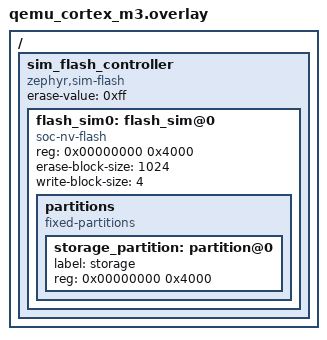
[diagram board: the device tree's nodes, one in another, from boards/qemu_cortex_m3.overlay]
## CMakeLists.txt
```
# SPDX-License-Identifier: Apache-2.0
cmake_minimum_required(VERSION 3.20.0)
find_package(Zephyr REQUIRED HINTS $ENV{ZEPHYR_BASE})
project(__name___tests)

set(LIB ${CMAKE_CURRENT_LIST_DIR}/../../lib)
target_include_directories(app PRIVATE ${LIB}/cfg)
target_sources(app PRIVATE ${LIB}/cfg/cfg.c src/test_cfg.c)
```

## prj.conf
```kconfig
CONFIG_ZTEST=y
CONFIG_FLASH=y
CONFIG_FLASH_MAP=y
CONFIG_NVS=y
CONFIG_SETTINGS=y
CONFIG_SETTINGS_NVS=y
```

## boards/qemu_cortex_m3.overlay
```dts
/* qemu has no writable flash: a 16 KiB simulated one with the storage_partition settings use */
/ {
	sim_flash_controller: sim_flash_controller {
		compatible = "zephyr,sim-flash";
		#address-cells = <1>;
		#size-cells = <1>;
		erase-value = <0xff>;

		flash_sim0: flash_sim@0 {
			compatible = "soc-nv-flash";
			reg = <0x00000000 0x4000>;
			erase-block-size = <1024>;
			write-block-size = <4>;

			partitions {
				compatible = "fixed-partitions";
				#address-cells = <1>;
				#size-cells = <1>;

				storage_partition: partition@0 {
					label = "storage";
					reg = <0x00000000 0x4000>;
				};
			};
		};
	};
};
```

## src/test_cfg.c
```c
#include <string.h>
#include <zephyr/ztest.h>
#include <zephyr/storage/flash_map.h>
#include "cfg.h"

static void *setup(void)
{
	const struct flash_area *fa;

	zassert_ok(flash_area_open(PARTITION_ID(storage_partition), &fa));
	zassert_ok(flash_area_erase(fa, 0, fa->fa_size));
	flash_area_close(fa);
	return NULL;
}

ZTEST_SUITE(cfg, NULL, setup, NULL, NULL, NULL);

ZTEST(cfg, test_1_defaults_on_empty_flash)
{
	zassert_ok(cfg_load());
	zassert_equal(cfg.boots, 0);
	zassert_str_equal(cfg.name, "__name__");
}

ZTEST(cfg, test_2_round_trip)
{
	zassert_ok(cfg_load());
	cfg.boots = 5;
	strcpy(cfg.name, "unit-7");
	zassert_ok(cfg_save());
	zassert_ok(cfg_load()); /* resets to defaults, then reads flash */
	zassert_equal(cfg.boots, 5);
	zassert_str_equal(cfg.name, "unit-7");
}
```
